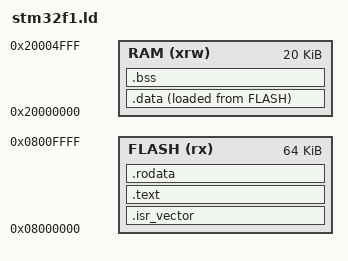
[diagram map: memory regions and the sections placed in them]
/**
 * @file    stm32f1.ld
 * @author  Rohit Nimkar <https://www.linkedin.com/in/rohit-nimkar>
 * @brief   Linker script for stm32f103c8t6 micro-controller
 * @version 1.2
 * @date    2024-01-07
 * 
 * @copyright Copyright (c) 2024
 * @attention
 * 
 * This software component is licensed by Rohit Nimkar under BSD 3-Clause license,
 * the "License"; You may not use this file except in compliance with the
 * License. You may obtain a copy of the License at: opensource.org/licenses/BSD-3-Clause
 *
 */

/* Entry Point */
ENTRY(Reset_Handler)

/* Highest address of the user mode stack */
_stack_top = ORIGIN(RAM) + LENGTH(RAM); /* end of "RAM" Ram type memory */

/* Memories definition */
MEMORY
{
  RAM     (xrw)   : ORIGIN = 0x20000000,   LENGTH = 20K
  FLASH   (rx)    : ORIGIN = 0x8000000,   LENGTH = 64K
}

/* Sections */
SECTIONS
{
  /* The startup code into "FLASH" Rom type memory */
  .isr_vector :
  {
    . = ALIGN(4);
    KEEP(*(.isr_vector)) /* Startup code */
    . = ALIGN(4);
  } >FLASH

  /* The program code and other data into "FLASH" Rom type memory */
  .text :
  {
    . = ALIGN(4);
    *(.text)           /* .text sections (code) */
    *(.text*)          /* .text* sections (code) */

    KEEP (*(.init))
    KEEP (*(.fini))

    . = ALIGN(4);
    _etext = .;        /* define a global symbols at end of code */
  } >FLASH

  /* Constant data into "FLASH" Rom type memory */
  .rodata :
  {
    . = ALIGN(4);
    *(.rodata)         /* .rodata sections (constants, strings, etc.) */
    *(.rodata*)        /* .rodata* sections (constants, strings, etc.) */
    . = ALIGN(4);
  } >FLASH

  /* Used by the startup to initialize data */
  _la_data = LOADADDR(.data);

  /* Initialized data sections into "RAM" Ram type memory */
  .data :
  {
    . = ALIGN(4);
    _sdata = .;        /* create a global symbol at data start */
    *(.data)           /* .data sections */
    *(.data*)          /* .data* sections */

    . = ALIGN(4);
    _edata = .;        /* define a global symbol at data end */

  } >RAM AT> FLASH

  /* Uninitialized data section into "RAM" Ram type memory */
  . = ALIGN(4);
  .bss :
  {
    /* This is used by the startup in order to initialize the .bss section */
    _sbss = .;         /* define a global symbol at bss start */
    __bss_start__ = _sbss;
    *(.bss)
    *(.bss*)
    *(COMMON)

    . = ALIGN(4);
    _ebss = .;         /* define a global symbol at bss end */
    __bss_end__ = _ebss;
  } >RAM

  /* Remove information from the compiler libraries */
  /DISCARD/ :
  {
    libc.a ( * )
    libm.a ( * )
    libgcc.a ( * )
  }

}
